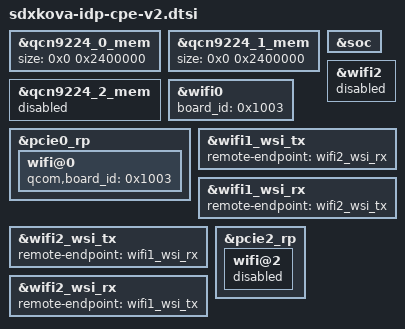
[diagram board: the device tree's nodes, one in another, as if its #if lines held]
// SPDX-License-Identifier: BSD-3-Clause
/*
 * Copyright (c) Qualcomm Technologies, Inc. and/or its subsidiaries.
 */

#include "sdxkova-idp-cpe.dtsi"
#include "sdxkova-qcn9224.dtsi"

&qcn9224_0_mem {
#ifdef __WLAN_LITE_PROFILE__
	size = <0x0 0x2400000>;
#endif
};

&qcn9224_1_mem {
#ifdef __WLAN_LITE_PROFILE__
	size = <0x0 0x2400000>;
#endif
};

&qcn9224_2_mem {
	status = "disabled";
};

&soc {
};

&wifi0 {
	board_id = <0x1003>;
};

&wifi2 {
	status = "disabled";
};

&qcn9224_2_mem {
	status = "disabled";
};

#ifdef __WLAN_UD__
&pcie0_rp {
	wifi@0 {
		qcom,board_id = <0x1003>;
	};
};

&wifi1_wsi_tx {
	remote-endpoint = <&wifi2_wsi_rx>;
};


&wifi1_wsi_rx {
	remote-endpoint = <&wifi2_wsi_tx>;
};

&wifi2_wsi_tx {
	remote-endpoint = <&wifi1_wsi_rx>;
};


&wifi2_wsi_rx {
	remote-endpoint = <&wifi1_wsi_tx>;
};

&pcie2_rp {
	wifi@2 {
		status = "disabled";
	};
};

#endif
